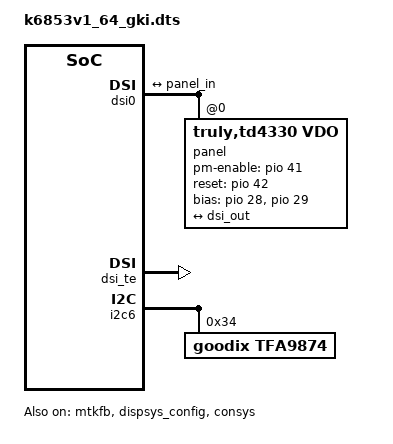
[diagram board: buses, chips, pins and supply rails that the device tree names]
// SPDX-License-Identifier: (GPL-2.0 OR MIT)
/*
 * Copyright (C) 2020 MediaTek Inc.
 * Author: Chun-Hung Wu <chun-hung.wu@mediatek.com>
 */
/dts-v1/;
/plugin/;
#include <dt-bindings/interrupt-controller/arm-gic.h>
#include <dt-bindings/interrupt-controller/irq.h>
#include <dt-bindings/pinctrl/mt6853-pinfunc.h>
#include <dt-bindings/clock/mt6873-clk.h>

&gpio{
	gpio_init_default = <0 0 0 0 1 0 1>,
		<1 0 0 0 1 1 1>,
		<2 0 0 0 1 1 1>,
		<3 0 0 0 1 0 1>,
		<4 0 0 0 1 1 1>,
		<5 0 0 0 1 0 1>,
		<6 0 1 0 1 0 1>,
		<7 0 1 0 1 0 1>,
		<8 7 0 0 1 0 1>,
		<9 0 0 0 1 1 1>,
		<10 0 0 0 1 1 1>,
		<11 0 1 0 1 0 1>,
		<12 2 0 0 1 0 1>,
		<13 2 0 0 1 0 1>,
		<14 0 0 0 1 1 1>,
		<15 0 1 0 1 0 1>,
		<16 7 0 0 1 0 1>,
		<17 7 0 0 1 0 1>,
		<18 7 0 0 1 0 1>,
		<19 7 0 0 1 0 1>,
		<20 1 0 0 0 0 1>,
		<21 1 0 0 0 0 1>,
		<22 1 0 0 0 0 1>,
		<23 1 0 0 1 0 1>,
		<24 2 0 0 0 0 1>,
		<25 2 0 0 0 0 1>,
		<26 2 0 0 0 0 1>,
		<27 2 0 0 1 0 1>,
		<28 4 0 0 1 1 1>,
		<29 4 0 0 0 0 1>,
		<30 4 0 0 0 0 1>,
		<31 4 0 0 1 1 1>,
		<32 0 0 0 1 1 1>,
		<33 1 0 0 0 0 1>,
		<34 1 0 0 0 0 1>,
		<35 1 0 0 1 0 1>,
		<36 1 0 0 0 0 1>,
		<37 0 0 0 1 0 1>,
		<38 0 0 0 1 0 1>,
		<39 0 0 0 1 0 1>,
		<40 0 1 0 1 0 1>,
		<41 0 1 0 1 0 1>,
		<42 7 0 0 1 0 1>,
		<43 7 0 0 1 0 1>,
		<44 7 0 0 1 0 1>,
		<45 7 0 0 0 0 1>,
		<46 7 0 0 1 0 1>,
		<47 7 0 0 1 0 1>,
		<48 7 0 0 1 0 1>,
		<49 1 0 0 0 0 1>,
		<50 1 0 0 0 0 1>,
		<51 1 0 0 0 0 1>,
		<52 1 0 0 0 0 1>,
		<53 0 1 0 1 0 1>,
		<54 0 1 0 1 0 1>,
		<55 0 1 0 1 0 1>,
		<56 0 1 0 1 0 1>,
		<57 0 0 0 1 0 1>,
		<58 0 1 0 1 0 1>,
		<59 1 0 0 1 0 1>,
		<60 0 1 0 1 0 1>,
		<61 1 0 0 1 1 1>,
		<62 1 0 0 0 0 1>,
		<63 1 0 0 1 1 1>,
		<64 1 0 0 0 0 1>,
		<77 1 0 0 1 1 1>,
		<78 0 0 0 1 0 1>,
		<79 1 0 0 1 1 1>,
		<80 0 1 0 1 0 1>,
		<81 3 0 0 1 0 1>,
		<82 0 1 0 1 0 1>,
		<83 1 0 0 0 0 1>,
		<84 1 0 0 1 0 1>,
		<85 1 0 0 0 0 1>,
		<86 1 0 0 0 0 1>,
		<87 2 0 0 1 0 1>,
		<88 0 0 0 1 0 1>,
		<89 0 0 0 1 0 1>,
		<90 1 1 0 0 0 1>,
		<91 0 0 0 1 0 1>,
		<92 0 1 0 1 0 1>,
		<93 0 1 0 1 0 1>,
		<94 0 1 0 1 0 1>,
		<95 1 0 0 1 0 1>,
		<96 1 0 0 1 0 1>,
		<97 1 0 0 1 1 1>,
		<98 1 0 0 1 1 1>,
		<99 2 0 0 1 1 1>,
		<100 2 0 0 1 1 1>,
		<101 1 0 0 1 1 1>,
		<102 1 0 0 1 1 1>,
		<103 1 0 0 1 1 1>,
		<104 1 0 0 1 1 1>,
		<105 1 0 0 1 1 1>,
		<106 1 0 0 1 1 1>,
		<107 0 0 0 1 0 1>,
		<108 0 0 0 1 0 1>,
		<109 1 0 0 1 1 1>,
		<110 1 0 0 1 1 1>,
		<111 7 0 0 1 0 1>,
		<112 7 0 0 1 0 1>,
		<113 1 0 0 1 1 1>,
		<114 1 0 0 1 1 1>,
		<115 1 0 0 0 0 1>,
		<116 1 0 0 0 0 1>,
		<117 1 0 0 0 0 1>,
		<118 1 0 0 0 0 1>,
		<119 1 0 0 0 0 1>,
		<120 1 0 0 0 0 1>,
		<121 1 0 0 1 1 1>,
		<122 1 0 0 1 1 1>,
		<123 1 0 0 0 0 1>,
		<124 1 0 0 0 0 1>,
		<125 1 0 0 0 0 1>,
		<126 1 0 0 1 1 1>,
		<127 1 0 0 1 1 1>,
		<128 1 0 0 1 1 1>,
		<129 1 0 0 1 1 1>,
		<130 1 0 0 1 1 1>,
		<131 0 1 0 1 0 1>,
		<132 0 1 0 1 0 1>,
		<133 0 1 0 1 0 1>,
		<134 0 1 0 1 0 1>,
		<135 0 1 0 1 0 1>,
		<136 0 1 1 1 0 1>,
		<137 0 1 0 1 0 1>,
		<138 0 1 0 1 0 1>,
		<139 0 1 0 1 0 1>,
		<140 0 1 0 1 0 1>,
		<141 2 0 0 1 0 1>,
		<142 2 0 0 1 0 1>,
		<143 1 0 0 0 0 1>,
		<144 1 0 0 0 0 1>,
		<145 1 0 0 0 0 1>,
		<146 1 0 0 0 0 1>,
		<147 1 0 0 0 0 1>,
		<148 1 0 0 0 0 1>,
		<149 1 0 0 1 0 1>,
		<150 1 0 0 1 0 1>,
		<151 1 0 0 1 0 1>,
		<152 1 0 0 0 0 1>,
		<153 1 0 0 0 0 1>,
		<154 1 0 0 0 0 1>,
		<155 1 0 0 0 0 1>,
		<156 1 0 0 0 0 1>,
		<157 1 0 0 0 0 1>,
		<158 1 0 0 0 0 1>,
		<159 1 0 0 1 0 1>,
		<160 1 0 0 1 0 1>,
		<161 1 0 0 1 0 1>,
		<162 1 0 0 0 0 0>,
		<163 1 0 0 1 0 0>,
		<164 1 0 0 1 0 1>,
		<165 1 0 0 1 0 1>,
		<166 1 0 0 0 0 1>,
		<167 1 0 0 0 0 1>,
		<168 1 0 0 0 0 1>,
		<169 1 0 0 0 0 1>,
		<170 1 0 0 0 0 1>,
		<171 0 1 1 0 0 1>,
		<172 1 0 0 0 0 1>,
		<173 1 0 0 0 0 1>,
		<174 1 0 0 0 0 1>,
		<175 1 0 0 0 0 1>,
		<176 1 0 0 0 0 1>,
		<177 1 0 0 0 0 1>,
		<178 1 0 0 0 0 1>,
		<179 1 0 0 0 0 1>,
		<180 1 0 0 0 0 1>,
		<181 1 0 0 0 0 1>,
		<182 1 0 0 0 0 1>,
		<183 1 0 0 0 0 1>,
		<184 1 0 0 0 0 1>,
		<185 1 0 0 0 0 1>,
		<186 1 0 0 0 0 1>,
		<187 1 0 0 0 0 1>,
		<188 1 0 0 0 0 0>,
		<189 1 0 0 1 0 0>,
		<190 1 0 0 0 0 0>,
		<191 1 0 0 1 0 0>,
		<192 0 0 0 1 0 1>,
		<193 0 0 0 1 0 1>,
		<194 0 0 0 1 0 1>,
		<195 0 0 0 1 0 1>,
		<196 0 0 0 1 0 1>,
		<197 0 0 0 1 0 1>,
		<198 0 0 0 1 0 1>,
		<199 0 0 0 1 0 1>,
		<200 0 0 0 1 0 1>,
		<201 0 0 0 1 0 1>,
		<202 0 0 0 1 0 1>,
		<203 0 0 0 1 0 0>,
		<204 0 0 0 1 0 0>,
		<205 0 0 0 1 0 0>,
		<206 0 0 0 1 0 0>,
		<207 0 0 0 1 0 0>,
		<208 0 0 0 1 0 0>,
		<209 0 0 0 1 0 0>,
		<210 0 0 0 1 0 0>,
		<211 0 0 0 1 0 0>;
};

&chosen {
	atag,videolfb-fb_base_l = <0x7e605000>;
	atag,videolfb-fb_base_h = <0x0>;
	atag,videolfb-islcmfound = <1>;
	atag,videolfb-islcm_inited = <0>;
	atag,videolfb-fps= <6000>;
	atag,videolfb-vramSize= <0x1be0000>;
	atag,videolfb-lcmname=
		"td4330_fhdp_dsi_vdo_auo_rt5081_drv";
};

&pio {
	mtkfb_pins_lcd_bias_enp1: lcd_bias_enp1_gpio {
		pins_cmd_dat {
			pinmux = <PINMUX_GPIO28__FUNC_GPIO28>;
			slew-rate = <1>;
			output-high;
		};
	};

	mtkfb_pins_lcd_bias_enp0: lcd_bias_enp0_gpio {
		pins_cmd_dat {
			pinmux = <PINMUX_GPIO28__FUNC_GPIO28>;
			slew-rate = <1>;
			output-low;
		};
	};

	mtkfb_pins_lcd_bias_enn1: lcd_bias_enn1_gpio {
		pins_cmd_dat {
			pinmux = <PINMUX_GPIO29__FUNC_GPIO29>;
			slew-rate = <1>;
			output-high;
		};
	};

	mtkfb_pins_lcd_bias_enn0: lcd_bias_enn0_gpio {
		pins_cmd_dat {
			pinmux = <PINMUX_GPIO29__FUNC_GPIO29>;
			slew-rate = <1>;
			output-low;
		};
	};

	mtkfb_pins_lcm_rst_out1_gpio: lcm_rst_out1_gpio {
		pins_cmd_dat {
			pinmux = <PINMUX_GPIO42__FUNC_GPIO42>;
			slew-rate = <1>;
			output-high;
		};
	};

	mtkfb_pins_lcm_rst_out0_gpio: lcm_rst_out0_gpio {
		pins_cmd_dat {
			pinmux = <PINMUX_GPIO42__FUNC_GPIO42>;
			slew-rate = <1>;
			output-low;
		};
	};
	mtkfb_pins_lcm_dsi_te: lcm_dsi_te {
		pins_cmd_dat {
			/* pinmux = <PINMUX_GPIO41__FUNC_DSI_TE>; */
		};
	};
};

&mtkfb {
	pinctrl-names = "lcd_bias_enp1_gpio", "lcd_bias_enp0_gpio",
			"lcd_bias_enn1_gpio", "lcd_bias_enn0_gpio",
			"lcm_rst_out1_gpio", "lcm_rst_out0_gpio",
			"mode_te_te";
	pinctrl-0 = <&mtkfb_pins_lcd_bias_enp1>;
	pinctrl-1 = <&mtkfb_pins_lcd_bias_enp0>;
	pinctrl-2 = <&mtkfb_pins_lcd_bias_enn1>;
	pinctrl-3 = <&mtkfb_pins_lcd_bias_enn0>;
	pinctrl-4 = <&mtkfb_pins_lcm_rst_out1_gpio>;
	pinctrl-5 = <&mtkfb_pins_lcm_rst_out0_gpio>;
	pinctrl-6 = <&mtkfb_pins_lcm_dsi_te>;
	status = "okay";
};

&dispsys_config {
	pinctrl-names =
			"lcm_rst_out1_gpio", "lcm_rst_out0_gpio",
			"mode_te_te";
	pinctrl-0 = <&mtkfb_pins_lcm_rst_out1_gpio>;
	pinctrl-1 = <&mtkfb_pins_lcm_rst_out0_gpio>;
	pinctrl-2 = <&mtkfb_pins_lcm_dsi_te>;
	status = "okay";
};

&dsi0 {
	status = "okay";
	#address-cells = <1>;
	#size-cells = <0>;
	panel@0 {
		compatible = "truly,td4330,vdo";
		reg = <0>;
		pm-enable-gpios = <&pio 41 0>;
		reset-gpios = <&pio 42 0>;
		bias-gpios = <&pio 28 0>,
			<&pio 29 0>;
		pinctrl-names = "default";
		port {
			panel_in: endpoint {
				remote-endpoint = <&dsi_out>;
			};
		};
	};
	ports {
		port {
			dsi_out: endpoint {
				remote-endpoint = <&panel_in>;
			};
		};
	};
};

&dsi_te {
	interrupt-parent = <&pio>;
	interrupts = <41 1 41 1>;
	status = "okay";
};

&i2c6 {
	tfa9874: tfa9874@34 {
		compatible = "goodix,tfa9874";
		#sound-dai-cells = <0>;
		reg = <0x34>;
		status = "okay";
	};
};

&sound {
	mediatek,speaker-codec {
		sound-dai = <&tfa9874>;
	};
};

/*End of this file, DO NOT ADD ANYTHING HERE*/

/* CONSYS GPIO standardization */
&pio {
	consys_pins_default: consys_default {
	};
	gpslna_pins_init: gpslna@0 {
		pins_cmd_dat {
			pinmux = <PINMUX_GPIO162__FUNC_GPIO162>;
			slew-rate = <0>;
			bias-disable;
			output-low;
		};
	};
	gpslna_pins_oh: gpslna@1 {
		pins_cmd_dat {
			pinmux = <PINMUX_GPIO162__FUNC_GPIO162>;
			slew-rate = <1>;
			output-high;
		};
	};
	gpslna_pins_ol: gpslna@2 {
		pins_cmd_dat {
			pinmux = <PINMUX_GPIO162__FUNC_GPIO162>;
			slew-rate = <1>;
			output-low;
		};
	};
};

&consys {
	pinctrl-names = "default", "gps_lna_state_init",
		"gps_lna_state_oh", "gps_lna_state_ol";
	pinctrl-0 = <&consys_pins_default>;
	pinctrl-1 = <&gpslna_pins_init>;
	pinctrl-2 = <&gpslna_pins_oh>;
	pinctrl-3 = <&gpslna_pins_ol>;
	status = "okay";
};

/* CONSYS end */
